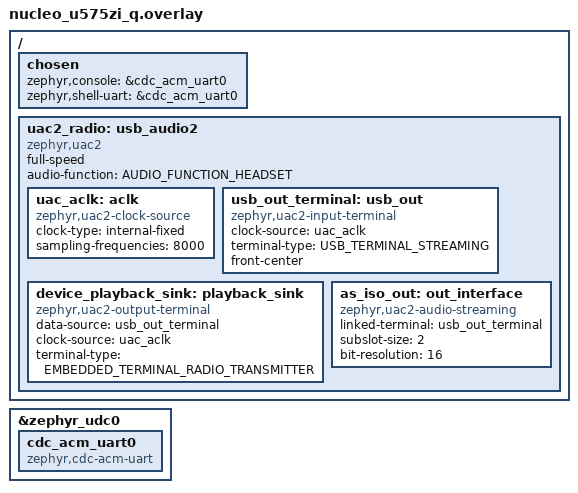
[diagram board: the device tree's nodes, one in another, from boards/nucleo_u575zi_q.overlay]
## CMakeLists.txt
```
cmake_minimum_required(VERSION 3.13.1)
find_package(Zephyr REQUIRED HINTS $ENV{ZEPHYR_BASE})

project(app LANGUAGES C CXX ASM)

target_sources(app PRIVATE src/version_shell.cpp)

if (CONFIG_ETL)
    target_sources(app PRIVATE src/etl_error_handler.cpp)
endif()

if (CONFIG_BOARD_NATIVE_SIM)
    # native_sim has no USB and no hardware-timed audio (analog-audio-in/out are
    # STM32-only); the SA818 driver runs AT/UART + control GPIOs only.
    target_sources(app PRIVATE src/main.cpp)
elseif (CONFIG_USB_DEVICE_STACK_NEXT)
    # Real hardware: 3-class USB composite (CDC-ACM + UAC2 + DFU).
    include(${ZEPHYR_BASE}/samples/subsys/usb/common/common.cmake)
    # SA818 driver public headers (<sa818/sa818.h> etc.) are only exposed via the
    # driver's own library-private include path; the app target needs it too,
    # same as subsys/module/CMakeLists.txt does for CONFIG_MODULE_SA818 and
    # tests/usb_audio/CMakeLists.txt does for this same pair of sources.
    target_include_directories(app PRIVATE
        ${CMAKE_CURRENT_LIST_DIR}/../drivers/radio/sa818
    )
    target_sources(app PRIVATE
        src/main_usb_audio.cpp
        src/usb_audio_bridge.cpp
        src/audio_stream.cpp
        src/feedback.cpp
        src/boot_confirm/health_gate.cpp
        src/boot_confirm/boot_confirm_fm.cpp
    )
    target_include_directories(app PRIVATE ${CMAKE_CURRENT_LIST_DIR}/src/boot_confirm)
    # DFU runtime->DFU-mode switch is prod-only (MCUboot); guard so the bare build never compiles it.
    if(CONFIG_BOOTLOADER_MCUBOOT)
        target_sources(app PRIVATE src/dfu_mode.cpp)
    endif()
    # Test-only bench loopback shell command (SA818 bypass); default-off Kconfig.
    if(CONFIG_FM_TEST_LOOPBACK)
        target_sources(app PRIVATE src/audio_shell.cpp)
    endif()
else()
    target_sources(app PRIVATE src/main.cpp)
endif()
```

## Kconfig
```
config FM_BOOT_CONFIRM_SKIP_SA818
	bool "Skip the SA818 handshake in the boot-confirm health gate"
	default n
	help
	  Bench/HIL-only. Drops the SA818 AT-handshake criterion from the
	  boot-confirm health gate, so a trial image can self-confirm on a
	  bench that has no working SA818 (no radio / no 12 V rail) using
	  only the USB-enumerated and shell-active criteria. Without this,
	  the SA818 probe never succeeds and every trial image reverts.
	  NEVER enable this in a production build.

menu "Zephyr"
source "Kconfig.zephyr"
endmenu

config FM_TEST_LOOPBACK
	bool "Test-only internal UAC2 audio loopback (SA818 bypass)"
	default n
	depends on USB_DEVICE_STACK_NEXT && SHELL
	help
	  Bench test mode. When armed at runtime it bridges the UAC2 OUT stream
	  (USB host -> device) straight back into the UAC2 IN stream
	  (device -> USB host), bypassing the SA818 radio entirely. Adds an
	  `audio loopback on|off|status` shell command to arm it. Intended for
	  hardware-in-the-loop verification of the host-side audio path without a
	  working radio link. Default n; never enable in a production build.

module = APP
module-str = APP
source "subsys/logging/Kconfig.template.log_config"
```

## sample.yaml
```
sample:
  description: FM Board Application
  name: fm-application

tests:
  fm.app.build:
    build_only: true
    integration_platforms:
      - fm_board
      - native_sim/native/64
  fm.app.loopback.build:
    # Build-only: verify the test-mode UAC2 loopback (SA818 bypass) compiles into
    # the fm_board app with CONFIG_FM_TEST_LOOPBACK=y. Runtime verification of the
    # audio routing is deferred to the HIL bench.
    build_only: true
    extra_configs:
      - CONFIG_FM_TEST_LOOPBACK=y
    platform_allow:
      - fm_board
    integration_platforms:
      - fm_board
    tags:
      - usb
      - audio
      - loopback
  fm.app.bench_skip_sa818.build:
    # Build-only: verify the boot-confirm health gate compiles with the SA818
    # criterion dropped (CONFIG_FM_BOOT_CONFIRM_SKIP_SA818=y) for HIL/bench use
    # without a working radio.
    build_only: true
    extra_configs:
      - CONFIG_FM_BOOT_CONFIRM_SKIP_SA818=y
    platform_allow:
      - fm_board
    integration_platforms:
      - fm_board
```

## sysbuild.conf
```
# Copyright (c) 2026 OE5XRX
# SPDX-License-Identifier: LGPL-3.0-or-later
#
# Sysbuild configuration for fm_board MCUboot + application build.
# This file is picked up automatically when building with --sysbuild.

# Build MCUboot together with the signed application.
SB_CONFIG_BOOTLOADER_MCUBOOT=y

# Swap-using-offset: scratch-less, interrupt-safe rollback (current Zephyr default).
SB_CONFIG_MCUBOOT_MODE_SWAP_USING_OFFSET=y

# ECDSA-P256 signatures (HW-accelerated by the U5 PKA in future; tinycrypt for now).
SB_CONFIG_BOOT_SIGNATURE_TYPE_ECDSA_P256=y

# Local + CI builds use MCUboot's built-in development key (root-ec-p256.pem in
# the mcuboot tree) — reproducible, not secret. Real releases override this with
# the OE5XRX production key via the CLI (-DSB_CONFIG_BOOT_SIGNATURE_KEY_FILE),
# materialized in .github/workflows/release.yml from the org secret. Never set a
# key file path here (would risk committing the key). See
# docs/superpowers/specs/2026-09-12-fw-production-signing-key-design.md.
```

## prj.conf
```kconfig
# Copyright (c) 2025 OE5XRX
# SPDX-License-Identifier: LGPL-3.0-or-later

# FM Board Application Configuration
# Main project configuration for SA818-based FM transceiver

# =============================================================================
# Language & Standard Library
# =============================================================================
CONFIG_CPP=y
CONFIG_STD_CPP20=y
CONFIG_EXTERNAL_LIBCPP=y

# =============================================================================
# Console & Serial
# =============================================================================
CONFIG_SERIAL=y
CONFIG_CONSOLE=y
CONFIG_UART_CONSOLE=y
CONFIG_PRINTK=y

# =============================================================================
# Shell Interface
# =============================================================================
CONFIG_SHELL=y
CONFIG_SHELL_BACKEND_SERIAL=y
CONFIG_SHELL_PROMPT_UART="fm> "

# Shell subsystem commands
CONFIG_KERNEL_SHELL=y
CONFIG_DEVICE_SHELL=y

# =============================================================================
# Storage
# =============================================================================
CONFIG_EEPROM=y
CONFIG_EEPROM_SHELL=y

# =============================================================================
# Device identity (STM32 96-bit UID)
# =============================================================================
# hwinfo_get_device_id() backs the runtime UID reported in `module fm describe`
# (identity.uid). On native_sim hwinfo returns -ENOSYS, so the provider falls
# back to a persisted synthetic UID (uid_source=synthetic).
CONFIG_HWINFO=y

# =============================================================================
# Peripherals
# =============================================================================

# Audio (RX capture / TX playback) is handled by the analog-audio-in /
# analog-audio-out drivers, which drive the conversions directly via STM32 LL +
# DMA. They still `select ADC`/`select DAC` so the Zephyr adc_stm32/dac_stm32
# subsystems bring the peripherals up (clocks + pinctrl) and coexist with the
# LL data path — the subsystems' streaming APIs themselves are not used.

# GPIO - SA818 control signals
CONFIG_GPIO=y
CONFIG_GPIO_SHELL=y

# UART - SA818 AT command interface
CONFIG_UART_INTERRUPT_DRIVEN=y

# =============================================================================
# Radio Driver
# =============================================================================
CONFIG_SA818=y
CONFIG_SA818_SHELL=y

# =============================================================================
# Logging
# =============================================================================
# Logs deliberately stay on the CDC-ACM control UART, but MUST route ONLY
# through the shell log backend -- NOT a second, direct UART backend.
#
# CONFIG_SHELL_BACKEND_SERIAL enables CONFIG_SHELL_LOG_BACKEND (default y): the
# shell thread serializes log flushing with its own shell_print output, so a
# MODULE-* protocol response line is emitted whole. A direct CONFIG_LOG_BACKEND_UART
# is a SECOND, async writer (LOG_PROCESS_THREAD, deferred mode) to the same UART
# with no mutual exclusion vs. the shell -- it splits MODULE-* lines mid-string and
# makes the station-agent discovery handshake flap OFFLINE. So it stays OFF.
CONFIG_LOG=y
CONFIG_LOG_DEFAULT_LEVEL=3
CONFIG_SHELL_LOG_BACKEND=y
# (CONFIG_LOG_BACKEND_UART intentionally NOT set -- see comment above.)

# =============================================================================
# Embedded Template Library (ETL)
# =============================================================================
# No-alloc fixed-capacity containers (etl::string/vector/map...). ETL routes
# runtime errors to a registered handler (see app/src/etl_error_handler.cpp)
# instead of throwing (exceptions stay disabled).
CONFIG_ETL=y
CONFIG_ETL_LOG_ERRORS=y

# =============================================================================
# Module Platform (self-describing capability interface)
# =============================================================================
# Ship the SAME interface the Twister suite tests: `module fm describe` must
# answer on the shipped app binary, not only in tests/sim_shell. MODULE_SA818
# depends on SA818 (enabled above) and selects CBPRINTF_FP_SUPPORT (needed for
# the %.4f floats in MODULE-RESULT).
CONFIG_MODULE=y
CONFIG_MODULE_SA818=y

# =============================================================================
# Reboot support
# =============================================================================
# Required by sys_reboot() used in h_reboot() (health-gate deadline revert)
# and the wdt_cb backstop timer (task_wdt stall path when the IWDG is not
# armed, prod-only).  Minimal symbol; safe in both bare and prod builds.
CONFIG_REBOOT=y

# =============================================================================
# Fault handling
# =============================================================================
# Reboot on any fatal error (bus/usage/MPU/stack-overflow fault) instead of
# halting the core forever. A halted core takes USB down with it, so the device
# just goes silent and dead until a physical power cycle -- exactly what a shell
# stack overflow used to do. Rebooting instead: the fault handler still prints
# the ESF/reason to the log UART first, then resets, so USB re-enumerates and the
# failure is observable (and on the prod/MCUboot build a persistently-faulting
# trial image is reverted by the health-gate + IWDG). Trade-off: a deterministic
# fault becomes a reboot loop rather than a hang -- intended: a visible loop is
# recoverable and diagnosable, a silent dead port is neither.
CONFIG_RESET_ON_FATAL_ERROR=y
```

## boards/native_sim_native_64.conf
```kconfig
# Copyright (c) 2025 OE5XRX
# SPDX-License-Identifier: LGPL-3.0-or-later

# Native Simulator Board-Specific Configuration
# Additional settings for native_sim/native/64 platform
# Enables hardware emulators for SA818 driver development

# =============================================================================
# Hardware Emulators
# =============================================================================

# GPIO Emulator - Required for SA818 control signals
# (power, PTT, H/L power, carrier detect). Audio is STM32-only (LL+DMA) and not
# instantiated on native_sim, so no ADC/DAC emulator is needed.
CONFIG_GPIO_EMUL=y

# =============================================================================
# UART Configuration
# =============================================================================
# UART PTY is automatically configured by native_sim
```

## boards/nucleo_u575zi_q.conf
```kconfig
CONFIG_USB_DEVICE_STACK_NEXT=y
CONFIG_USBD_CDC_ACM_CLASS=y
CONFIG_CDC_ACM_SERIAL_INITIALIZE_AT_BOOT=n

# UAC2
CONFIG_USBD_AUDIO2_CLASS=y

# Optional aber praktisch für Debug
CONFIG_USB_DEVICE_LOG_LEVEL_INF=y
CONFIG_LOG=y
```

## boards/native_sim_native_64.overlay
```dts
/*
 * Copyright (c) 2025 OE5XRX
 * SPDX-License-Identifier: LGPL-3.0-or-later
 *
 * Native Simulator Device Tree Overlay
 * Configures GPIO emulators for SA818 driver testing. The SA818 driver only
 * does AT/UART + control GPIOs; the hardware-timed audio path (analog-audio-in /
 * analog-audio-out) is STM32-only and is not instantiated on native_sim.
 */

/ {
  aliases {
    config-eeprom0 = &eeprom0;
    sa818 = &sa818;
  };

  /* Virtueller GPIO-Controller für SA818 */
  gpio_sa818: gpio_sa818 {
    compatible = "zephyr,gpio-emul";
    status = "okay";
    #gpio-cells = <2>;
    gpio-controller;
  };

  /* SA818 Device */
  sa818: sa818 {
    compatible = "sa,sa818";
    status = "okay";

    band = "vhf";
    uart = <&uart1>;

    h-l-power-gpios   = <&gpio_sa818 0 GPIO_ACTIVE_HIGH>;
    nptt-gpios        = <&gpio_sa818 1 GPIO_ACTIVE_LOW>;
    npower-down-gpios = <&gpio_sa818 2 GPIO_ACTIVE_LOW>;
    nsquelch-gpios    = <&gpio_sa818 3 GPIO_ACTIVE_LOW>;

    tx-enable-delay-ms = <20>;
    rx-settle-time-ms  = <50>;
  };
};

&uart1 {
  status = "okay";
  current-speed = <9600>;
};
```

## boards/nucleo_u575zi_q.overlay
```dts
#include <zephyr/dt-bindings/usb/audio.h>

/ {
  chosen {
    zephyr,console = &cdc_acm_uart0;
    zephyr,shell-uart = &cdc_acm_uart0;
  };

  /*
   * USB Audio Class 2 (UAC2)
   * - Playback (OUT): Host -> Device  (z.B. SA818 TX / DAC)
   * - Capture  (IN):  Device -> Host  (z.B. SA818 RX / ADC)
   *
   * If you only need playback first, you can comment out the IN path.
   */
  uac2_radio: usb_audio2 {
    compatible = "zephyr,uac2";
    status = "okay";
    full-speed;
		audio-function = <AUDIO_FUNCTION_HEADSET>;

    /* Clock Source: fixed 8kHz */
    uac_aclk: aclk {
      compatible = "zephyr,uac2-clock-source";
      clock-type = "internal-fixed";
      sampling-frequencies = <8000>;
      /* optionally:
       * frequency-control = "read-only";
       */
    };

    /* ===== Playback path (Host -> Device) ===== */

    usb_out_terminal: usb_out {
      compatible = "zephyr,uac2-input-terminal";
      clock-source = <&uac_aclk>;
      terminal-type = <USB_TERMINAL_STREAMING>;
      front-center; /* mono */
    };

    device_playback_sink: playback_sink {
      compatible = "zephyr,uac2-output-terminal";
      data-source = <&usb_out_terminal>;
      clock-source = <&uac_aclk>;
      /* pick something that matches your use-case; radio transmitter works too */
      terminal-type = <EMBEDDED_TERMINAL_RADIO_TRANSMITTER>;
    };

    as_iso_out: out_interface {
      compatible = "zephyr,uac2-audio-streaming";
      linked-terminal = <&usb_out_terminal>;
      subslot-size = <2>;
      bit-resolution = <16>;

      /*
       * If your host/ALSA expects asynchronous OUT with explicit feedback,
       * enable exactly one of these depending on how Zephyr currently implements it:
       *
       * - implicit-feedback;          (feedback on IN endpoint, no separate sync EP)
       * - feedback-endpoint;          (if such property exists in your Zephyr rev)
       *
       * Keep it commented for first bring-up and enable only if needed.
       */
      // implicit-feedback;
    };

    /* ===== Capture path (Device -> Host) ===== */

    //device_capture_source: capture_src {
    //  compatible = "zephyr,uac2-input-terminal";
    //  clock-source = <&uac_aclk>;
    //  terminal-type = <EMBEDDED_TERMINAL_RADIO_RECEIVER>;
    //  front-center; /* mono */
    //};
//
    //usb_in_terminal: usb_in {
    //  compatible = "zephyr,uac2-output-terminal";
    //  data-source = <&device_capture_source>;
    //  clock-source = <&uac_aclk>;
    //  terminal-type = <USB_TERMINAL_STREAMING>;
    //};
//
    //as_iso_in: in_interface {
    //  compatible = "zephyr,uac2-audio-streaming";
    //  linked-terminal = <&usb_in_terminal>;
    //  subslot-size = <2>;
    //  bit-resolution = <16>;
    //  // implicit-feedback;
    //};
  };
};

&zephyr_udc0 {
  cdc_acm_uart0: cdc_acm_uart0 {
    compatible = "zephyr,cdc-acm-uart";
  };
};
```

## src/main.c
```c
#include <zephyr/kernel.h>
#include <zephyr/sys/printk.h>

int main(void) {
  printk("Hello from Zephyr native_sim!\n");
  return 0;
}
```

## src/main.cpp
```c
/**
 * @file main.cpp
 * @brief FM Transceiver Main Application
 *
 * @copyright Copyright (c) 2026 OE5XRX
 * @spdx-license-identifier LGPL-3.0-or-later
 */

#include "audio_bridge/bridge.h"

#include <zephyr/device.h>
#include <zephyr/kernel.h>
#include <zephyr/logging/log.h>
#include <zephyr/sys/printk.h>

LOG_MODULE_REGISTER(main, LOG_LEVEL_INF);

int main(void) {}

/*
static int init_audio_bridge(void) {
  LOG_INF("FM Transceiver Application Starting");

  // Get device references from device tree
  const struct device *sa818_dev = DEVICE_DT_GET(DT_ALIAS(sa818));
  if (!device_is_ready(sa818_dev)) {
    LOG_ERR("SA818 device not ready");
    return -ENODEV;
  }
  LOG_INF("SA818 device ready");

  const struct device *uac2_dev = DEVICE_DT_GET(DT_NODELABEL(uac2_radio));
  if (!device_is_ready(uac2_dev)) {
    LOG_ERR("UAC2 device not ready");
    return -ENODEV;
  }
  LOG_INF("UAC2 device ready");

  // Initialize USB Audio Bridge to connect USB UAC2 with SA818
  int ret = oe5xrx::audio::UsbAudioBridge::instance().initialize(sa818_dev, uac2_dev);
  if (ret != 0) {
    LOG_ERR("Failed to initialize USB Audio Bridge: %d", ret);
    return ret;
  }

  LOG_INF("System initialization complete");
  LOG_INF("USB Audio <-> SA818 Radio bridge active");

  return 0;
}

SYS_INIT(init_audio_bridge, APPLICATION, 80);
*/
```

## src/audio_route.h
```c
/**
 * @file audio_route.h
 * @brief Pure routing decision for the UAC2 audio tap (USB OUT / SA818 RX).
 *
 * Single source of truth for *where* an audio chunk goes in the USB audio
 * bridge, factored out of usb_audio_bridge.cpp so the decision is unit-testable
 * on native_sim without the USB device stack (which the bridge translation unit
 * pulls in and native_sim does not provide). The functions are pure, constexpr,
 * and have no RTOS/USB/heap dependencies.
 *
 * Production behaviour (CONFIG_FM_TEST_LOOPBACK=n): the bridge always passes
 * loopback_enabled == false, so classify_out() folds to OutRoute::TxRing and
 * classify_sa818_rx() folds to Sa818RxRoute::RxRing -- the normal
 * USB OUT -> SA818 TX and SA818 RX -> USB IN paths, unchanged.
 *
 * @copyright Copyright (c) 2026 OE5XRX
 * @spdx-license-identifier LGPL-3.0-or-later
 */

#ifndef AUDIO_ROUTE_H_
#define AUDIO_ROUTE_H_

namespace audio_route {

/** Destination for a just-received USB OUT (host -> device) PCM chunk. */
enum class OutRoute {
  /** Normal operation: OUT -> TX ring -> SA818 TX. */
  TxRing,
  /** Test loopback armed and USB IN active: OUT -> RX ring -> USB IN (SA818 bypassed). */
  RxRingLoopback,
  /** Test loopback armed but USB IN inactive: drop. Buffering here would fill the
   *  RX ring with stale audio that plays out delayed (or overflows) once IN comes up. */
  DropInInactive,
};

/** Destination for an SA818 RX capture chunk. */
enum class Sa818RxRoute {
  /** Normal operation: SA818 RX -> RX ring -> USB IN. */
  RxRing,
  /** Test loopback armed: drop, so the real capture cannot mix into the RX ring
   *  which is carrying the looped-back USB OUT audio. */
  DropLoopback,
};

/**
 * @brief Decide where a USB OUT PCM chunk is routed.
 * @param loopback_enabled test loopback armed at runtime
 * @param rx_enabled USB IN (device -> host) terminal currently active
 */
constexpr OutRoute classify_out(bool loopback_enabled, bool rx_enabled) {
  if (!loopback_enabled) {
    return OutRoute::TxRing;
  }
  return rx_enabled ? OutRoute::RxRingLoopback : OutRoute::DropInInactive;
}

/**
 * @brief Decide where an SA818 RX capture chunk is routed.
 * @param loopback_enabled test loopback armed at runtime
 */
constexpr Sa818RxRoute classify_sa818_rx(bool loopback_enabled) {
  return loopback_enabled ? Sa818RxRoute::DropLoopback : Sa818RxRoute::RxRing;
}

} // namespace audio_route

#endif /* AUDIO_ROUTE_H_ */
```

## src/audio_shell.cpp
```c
/*
 * Copyright (c) 2026 OE5XRX
 * SPDX-License-Identifier: LGPL-3.0-or-later
 *
 * `audio` shell command tree — test-only UAC2 internal loopback control.
 *
 * `audio loopback on|off|status` arms/disarms the bench test mode that routes
 * USB OUT (host -> device) audio straight back to USB IN (device -> host),
 * bypassing the SA818. Lets the host-side audio path be exercised without a
 * working radio link (drives the HIL audio-loopback gate). Compiled only when
 * CONFIG_FM_TEST_LOOPBACK is set (default n); never present in a production
 * build.
 */
#include "usb_audio_bridge.h"

#include <zephyr/shell/shell.h>

static int cmd_loopback_on(const struct shell *sh, size_t argc, char **argv) {
  ARG_UNUSED(argc);
  ARG_UNUSED(argv);
  usb_audio_bridge_set_loopback(true);
  shell_print(sh, "loopback enabled (USB OUT -> USB IN, SA818 bypassed)");
  return 0;
}

static int cmd_loopback_off(const struct shell *sh, size_t argc, char **argv) {
  ARG_UNUSED(argc);
  ARG_UNUSED(argv);
  usb_audio_bridge_set_loopback(false);
  shell_print(sh, "loopback disabled");
  return 0;
}

static int cmd_loopback_status(const struct shell *sh, size_t argc, char **argv) {
  ARG_UNUSED(argc);
  ARG_UNUSED(argv);
  shell_print(sh, "loopback: %s", usb_audio_bridge_get_loopback() ? "on" : "off");
  return 0;
}

SHELL_STATIC_SUBCMD_SET_CREATE(loopback_subcmds, SHELL_CMD(on, NULL, "Enable internal UAC2 loopback (SA818 bypass)", cmd_loopback_on),
                               SHELL_CMD(off, NULL, "Disable internal UAC2 loopback", cmd_loopback_off),
                               SHELL_CMD(status, NULL, "Show loopback state", cmd_loopback_status), SHELL_SUBCMD_SET_END);

SHELL_STATIC_SUBCMD_SET_CREATE(audio_subcmds, SHELL_CMD(loopback, &loopback_subcmds, "Test-only UAC2 internal loopback (SA818 bypass)", NULL),
                               SHELL_SUBCMD_SET_END);

SHELL_CMD_REGISTER(audio, &audio_subcmds, "Audio test controls (bench/HIL only)", NULL);
```

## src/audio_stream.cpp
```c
/**
 * @file audio_stream.cpp
 * @brief Generic hardware-timed audio streaming bridge. See audio_stream.h.
 *
 * Bridges application audio callbacks to the hardware-timed capture/playback
 * backend (the analog-audio-in / analog-audio-out TIM+ADC/DAC+DMA modules). It
 * is radio-agnostic: the @p dev handle is opaque and only passed back to the
 * callbacks as context.
 *
 * @copyright Copyright (c) 2026 OE5XRX
 * @spdx-license-identifier LGPL-3.0-or-later
 */

#include "audio_stream.h"

#include <errno.h>
#include <zephyr/device.h>
#include <zephyr/kernel.h>
#include <zephyr/logging/log.h>

/* Require the DT node to be status=okay AND the driver Kconfig on. The device
 * is only instantiated via DT_INST_FOREACH_STATUS_OKAY, so an existing-but-
 * disabled node (or CONFIG_ANALOG_AUDIO_{IN,OUT}=n) has no device symbol and
 * DEVICE_DT_GET() would fail to link. Use HAS_STATUS(okay), not NODE_EXISTS. */
#if DT_NODE_HAS_STATUS(DT_NODELABEL(audio_in), okay) && IS_ENABLED(CONFIG_ANALOG_AUDIO_IN)
#include <oe5xrx/audio/analog_audio_in.h>
#define AUDIO_STREAM_HAVE_AAI 1
#endif

#if DT_NODE_HAS_STATUS(DT_NODELABEL(audio_out), okay) && IS_ENABLED(CONFIG_ANALOG_AUDIO_OUT)
#include <oe5xrx/audio/analog_audio_out.h>
#define AUDIO_STREAM_HAVE_AAO 1
#endif

LOG_MODULE_REGISTER(audio_stream, LOG_LEVEL_INF);

#define AUDIO_STREAM_SAMPLE_SIZE 2 /* 16-bit = 2 bytes */

/** Audio streaming context. */
struct audio_stream_ctx {
  const struct device *dev;
  struct audio_stream_callbacks callbacks;
  struct audio_format format;
  bool streaming;
};

/*
 * DESIGN NOTE: single global streaming context — only one audio stream can be
 * active at a time, which fits the single-radio system. Storing the context per
 * device would be needed to support several concurrent streams.
 */

/* Static mutex for the streaming context - initialized at compile time */
K_MUTEX_DEFINE(audio_stream_mutex);

static struct audio_stream_ctx audio_ctx;

#ifdef AUDIO_STREAM_HAVE_AAO
/* Hardware-timed TX playback pull-source for the analog-audio-out module. Runs
 * in that module's workqueue thread (thread context, may take a mutex). Sources
 * signed 16-bit PCM from the application via the tx_request callback. Returning
 * fewer than @p max samples (or 0 when there is no data) makes the module emit
 * mid-scale silence for the shortfall; the consumer gates whether any data is
 * available. Host PCM is little-endian, matching the Cortex-M, so the byte
 * buffer maps directly onto int16 samples with no swap. */
static size_t audio_stream_tx_src(int16_t *dst, size_t max, void *user) {
  struct audio_stream_ctx *ctx = static_cast<struct audio_stream_ctx *>(user);

  if (!ctx->callbacks.tx_request) {
    return 0;
  }
  size_t bytes = ctx->callbacks.tx_request(ctx->dev, reinterpret_cast<uint8_t *>(dst), max * AUDIO_STREAM_SAMPLE_SIZE, ctx->callbacks.user_data);
  /* Defend against a callback that returns more than requested; the division to
   * whole samples already rounds a stray odd byte down. */
  if (bytes > max * AUDIO_STREAM_SAMPLE_SIZE) {
    bytes = max * AUDIO_STREAM_SAMPLE_SIZE;
  }
  return bytes / AUDIO_STREAM_SAMPLE_SIZE;
}
#endif

#ifdef AUDIO_STREAM_HAVE_AAI
/* Hardware-timed RX samples from the analog-audio-in module. Runs in the module's
 * workqueue thread (not an ISR), so forwarding through rx_data (which may take a
 * mutex) is safe. */
static void audio_stream_on_rx_samples(const int16_t *samples, size_t count, void *user) {
  struct audio_stream_ctx *ctx = static_cast<struct audio_stream_ctx *>(user);

  if (ctx->callbacks.rx_data) {
    ctx->callbacks.rx_data(ctx->dev, reinterpret_cast<const uint8_t *>(samples), count * AUDIO_STREAM_SAMPLE_SIZE, ctx->callbacks.user_data);
  }
}
#endif

int audio_stream_register(const struct device *dev, const struct audio_stream_callbacks *callbacks) {
  if (!dev || !callbacks) {
    return -EINVAL;
  }

  /* Guard the shared context and refuse to swap callbacks under a running
   * stream (the backend threads read ctx->callbacks/ctx->dev while active). */
  k_mutex_lock(&audio_stream_mutex, K_FOREVER);
  if (audio_ctx.streaming) {
    k_mutex_unlock(&audio_stream_mutex);
    return -EBUSY;
  }
  audio_ctx.dev = dev;
  audio_ctx.callbacks = *callbacks;
  k_mutex_unlock(&audio_stream_mutex);

  LOG_INF("Audio callbacks registered");
  return 0;
}

int audio_stream_start(const struct device *dev, const struct audio_format *format) {
  if (!dev || !format) {
    return -EINVAL;
  }

  /* Hold the stream mutex across the whole start sequence — the state flip AND
   * the backend bring-up. Releasing it before starting the backends would open
   * a window where a concurrent stop() clears streaming while we are still
   * bringing hardware up, leaving the backends running with streaming == false.
   * The backend callbacks (tx_src / on_rx_samples) do not take this mutex, so
   * holding it across analog_audio_*_start() cannot deadlock. */
  k_mutex_lock(&audio_stream_mutex, K_FOREVER);
  if (audio_ctx.dev != dev) {
    /* start must run against the context bound by audio_stream_register();
     * a mismatch (or a start without a prior register, dev == NULL) would
     * later trip the dev checks in stop()/get_format(). */
    k_mutex_unlock(&audio_stream_mutex);
    LOG_ERR("audio_stream_start dev does not match registered context");
    return -EINVAL;
  }
  if (audio_ctx.streaming) {
    k_mutex_unlock(&audio_stream_mutex);
    LOG_WRN("Audio streaming already active");
    return 0;
  }
  audio_ctx.format = *format;
  audio_ctx.streaming = true;

  /* Count backends that actually came up. A single backend failing only
   * degrades that direction (RX-only or TX-only is still useful), so we keep
   * streaming. But if *no* backend is driving the callbacks — none compiled in,
   * or every one failed — then reporting success would be a lie: the rings
   * would never be drained/filled. In that case roll back and fail with
   * -ENODEV. */
  int started = 0;

#ifdef AUDIO_STREAM_HAVE_AAO
  /* Start the hardware-timed TX playback module; it pulls PCM via the source
   * callback. A failure only disables TX playback (RX still works), so surface
   * it loudly rather than fail the whole stream. */
  const struct device *aao_dev = DEVICE_DT_GET(DT_NODELABEL(audio_out));
  if (!device_is_ready(aao_dev)) {
    LOG_ERR("analog-audio-out device not ready (TX playback unavailable)");
  } else {
    int aao_ret = analog_audio_out_start(aao_dev, audio_stream_tx_src, &audio_ctx);
    if (aao_ret < 0) {
      LOG_ERR("analog-audio-out start failed: %d (TX playback unavailable)", aao_ret);
    } else {
      started++;
    }
  }
#endif

#ifdef AUDIO_STREAM_HAVE_AAI
  /* Start the hardware-timed RX capture module; it delivers PCM via the callback.
   * A failure only disables RX capture (TX still works), so surface it loudly
   * rather than fail the whole stream. Verify the device initialised before use
   * (per the driver-layer device_is_ready() convention) so a failed init cannot
   * leave analog_audio_in_start() operating on uninitialised runtime state. */
  const struct device *aai_dev = DEVICE_DT_GET(DT_NODELABEL(audio_in));
  if (!device_is_ready(aai_dev)) {
    LOG_ERR("analog-audio-in device not ready (RX capture unavailable)");
  } else {
    int aai_ret = analog_audio_in_start(aai_dev, audio_stream_on_rx_samples, &audio_ctx);
    if (aai_ret < 0) {
      LOG_ERR("analog-audio-in start failed: %d (RX capture unavailable)", aai_ret);
    } else {
      started++;
    }
  }
#endif

  if (started == 0) {
    audio_ctx.streaming = false;
    k_mutex_unlock(&audio_stream_mutex);
    LOG_ERR("No audio backend available; not streaming");
    return -ENODEV;
  }

  k_mutex_unlock(&audio_stream_mutex);
  LOG_INF("Audio streaming started: %u Hz, %u-bit, %u ch", format->sample_rate, format->bit_depth, format->channels);

  return 0;
}

int audio_stream_stop(const struct device *dev) {
  if (!dev) {
    return -EINVAL;
  }

  /* Hold the mutex across the state flip AND the backend teardown so stop() is
   * fully serialized against start() (see the note there) — otherwise the two
   * could interleave and leave a backend running with streaming == false. */
  k_mutex_lock(&audio_stream_mutex, K_FOREVER);
  if (audio_ctx.dev != dev) {
    /* Not the registered/active context — refuse to stop someone else's stream. */
    k_mutex_unlock(&audio_stream_mutex);
    return -EINVAL;
  }
  audio_ctx.streaming = false;

#ifdef AUDIO_STREAM_HAVE_AAO
  /* Consume the result: the analog_audio_* stop functions are warn_unused_result,
   * and GCC's attribute (unlike [[nodiscard]]) is NOT silenced by a (void) cast. */
  int aao_stop_ret = analog_audio_out_stop(DEVICE_DT_GET(DT_NODELABEL(audio_out)));
  if (aao_stop_ret < 0) {
    LOG_WRN("analog-audio-out stop returned %d", aao_stop_ret);
  }
#endif

#ifdef AUDIO_STREAM_HAVE_AAI
  int aai_stop_ret = analog_audio_in_stop(DEVICE_DT_GET(DT_NODELABEL(audio_in)));
  if (aai_stop_ret < 0) {
    LOG_WRN("analog-audio-in stop returned %d", aai_stop_ret);
  }
#endif

  k_mutex_unlock(&audio_stream_mutex);
  LOG_INF("Audio streaming stopped");
  return 0;
}

int audio_stream_get_format(const struct device *dev, struct audio_format *format) {
  if (!dev || !format) {
    return -EINVAL;
  }

  k_mutex_lock(&audio_stream_mutex, K_FOREVER);
  if (audio_ctx.dev != dev) {
    k_mutex_unlock(&audio_stream_mutex);
    return -EINVAL;
  }
  *format = audio_ctx.format;
  k_mutex_unlock(&audio_stream_mutex);
  return 0;
}
```

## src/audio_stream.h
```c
/**
 * @file audio_stream.h
 * @brief Generic hardware-timed audio streaming bridge
 *
 * Callback-based bidirectional audio streaming that connects an application
 * audio source/sink (USB, I2S, file, network, ...) to the hardware-timed
 * capture/playback backend. The sample timing is delegated to that backend
 * (currently the analog-audio-in / analog-audio-out TIM+ADC/DAC+DMA modules);
 * this layer only bridges PCM to/from the application callbacks.
 *
 * This module is intentionally radio-agnostic: it takes an opaque @p dev handle
 * that it passes straight back to the callbacks as context, and depends on no
 * particular transceiver driver. Swapping the audio backend (e.g. to an I2S
 * codec) is a change here, not in the radio driver.
 *
 * @copyright Copyright (c) 2026 OE5XRX
 * @spdx-license-identifier LGPL-3.0-or-later
 */

#ifndef OE5XRX_APP_AUDIO_STREAM_H_
#define OE5XRX_APP_AUDIO_STREAM_H_

#include <stddef.h>
#include <stdint.h>
#include <zephyr/device.h>

#ifdef __cplusplus
extern "C" {
#endif

/** Audio sample format. */
struct audio_format {
  uint32_t sample_rate; /**< Sample rate in Hz (typically 8000) */
  uint8_t bit_depth;    /**< Bits per sample (typically 16) */
  uint8_t channels;     /**< Number of channels (1=mono, 2=stereo) */
};

/**
 * @brief TX audio request callback
 *
 * Invoked when the playback backend needs PCM samples. Fill @p buffer and
 * return the number of bytes written (0 when no data is available).
 *
 * @param dev       Opaque context handle from audio_stream_register()
 * @param buffer    Buffer to fill with PCM audio
 * @param size      Number of bytes requested
 * @param user_data User data pointer from callback registration
 * @return Bytes written to @p buffer
 */
typedef size_t (*audio_stream_tx_request_cb)(const struct device *dev, uint8_t *buffer, size_t size, void *user_data);

/**
 * @brief RX audio data callback
 *
 * Invoked when the capture backend has PCM samples available.
 *
 * @param dev       Opaque context handle from audio_stream_register()
 * @param buffer    Buffer containing PCM audio
 * @param size      Number of bytes in @p buffer
 * @param user_data User data pointer from callback registration
 */
typedef void (*audio_stream_rx_data_cb)(const struct device *dev, const uint8_t *buffer, size_t size, void *user_data);

/** Audio streaming callbacks. */
struct audio_stream_callbacks {
  audio_stream_tx_request_cb tx_request; /**< TX audio request (playback) */
  audio_stream_rx_data_cb rx_data;       /**< RX audio available (capture) */
  void *user_data;                       /**< User data for the callbacks */
};

/**
 * @brief Register audio streaming callbacks.
 * @param dev       Opaque context handle passed back to the callbacks.
 * @param callbacks Callback structure.
 * @return 0 on success, negative errno otherwise.
 */
int audio_stream_register(const struct device *dev, const struct audio_stream_callbacks *callbacks);

/**
 * @brief Start audio streaming (starts the capture/playback backend).
 * @return 0 on success, negative errno otherwise.
 */
int audio_stream_start(const struct device *dev, const struct audio_format *format);

/**
 * @brief Stop audio streaming.
 * @return 0 on success, negative errno otherwise.
 */
int audio_stream_stop(const struct device *dev);

/**
 * @brief Get the current audio format.
 * @return 0 on success, negative errno otherwise.
 */
int audio_stream_get_format(const struct device *dev, struct audio_format *format);

#ifdef __cplusplus
}
#endif

#endif /* OE5XRX_APP_AUDIO_STREAM_H_ */
```

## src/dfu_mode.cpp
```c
/**
 * @file dfu_mode.cpp
 * @brief DFU-only mode context: composite→DFU switch and upgrade request.
 *
 * Mirrors the switch_to_dfu_mode() sequence from
 * zephyr/samples/subsys/usb/dfu/src/main.c, adapted for C++20 and the OE5XRX
 * project conventions (no dynamic allocation, no exceptions, no RTTI).
 *
 * Compiled only when CONFIG_BOOTLOADER_MCUBOOT is set (prod/sysbuild build).
 *
 * @copyright Copyright (c) 2026 OE5XRX
 * @spdx-license-identifier LGPL-3.0-or-later
 */

#ifdef CONFIG_BOOTLOADER_MCUBOOT

#include "dfu_mode.h"

#include <zephyr/dfu/mcuboot.h>
#include <zephyr/kernel.h>
#include <zephyr/logging/log.h>
#include <zephyr/sys/reboot.h>
#include <zephyr/usb/usbd.h>

extern "C" {
#include "sample_usbd.h"
}

LOG_MODULE_REGISTER(dfu_mode, LOG_LEVEL_INF);

/* ---------------------------------------------------------------------------
 * Deferred self-reboot after a completed DFU download.
 *
 * The remote station has no debugger/ST-Link, so the reset that triggers the
 * MCUboot swap must originate from the firmware itself over the USB/DFU path.
 * We must NOT reboot synchronously inside the USBD message callback: that would
 * cut off dfu-util's final DFU status / manifestation phase and it would report
 * an error instead of "Done".  Instead we schedule a short delayed cold reboot
 * so the DFU manifestation and USB status complete cleanly first, then reset.
 * --------------------------------------------------------------------------*/
static constexpr uint32_t DFU_REBOOT_DELAY_MS = 500;

static void dfu_reboot_work_handler(struct k_work *work) {
  ARG_UNUSED(work);
  LOG_INF("DFU: rebooting to let MCUboot swap in the new image");
  sys_reboot(SYS_REBOOT_COLD);
}

static K_WORK_DELAYABLE_DEFINE(dfu_reboot_work, dfu_reboot_work_handler);

/* ---------------------------------------------------------------------------
 * Static DFU-only USBD context.
 *
 * A separate USBD_DEVICE_DEFINE is required: the composite context is shut
 * down before DFU mode is entered, so we cannot reuse it.  The same UDC
 * controller node (zephyr_udc0) is shared — that is intentional; only one
 * context is active at a time.
 *
 * VID/PID reuse the same CONFIG_SAMPLE_USBD_VID / CONFIG_SAMPLE_USBD_PID
 * values as the composite so dfu-util can identify the device consistently.
 * --------------------------------------------------------------------------*/
USBD_DEVICE_DEFINE(dfu_usbd, DEVICE_DT_GET(DT_NODELABEL(zephyr_udc0)), CONFIG_SAMPLE_USBD_VID, CONFIG_SAMPLE_USBD_PID);

/* Language descriptor (mandatory, must be added before configurations). */
USBD_DESC_LANG_DEFINE(dfu_lang);

/* Configuration descriptors for FS (and optionally HS). */
USBD_DESC_CONFIG_DEFINE(dfu_fs_cfg_desc, "DFU FS Configuration");
USBD_DESC_CONFIG_DEFINE(dfu_hs_cfg_desc, "DFU HS Configuration");

static const uint8_t dfu_cfg_attributes =
    (IS_ENABLED(CONFIG_SAMPLE_USBD_SELF_POWERED) ? USB_SCD_SELF_POWERED : 0) | (IS_ENABLED(CONFIG_SAMPLE_USBD_REMOTE_WAKEUP) ? USB_SCD_REMOTE_WAKEUP : 0);

USBD_CONFIGURATION_DEFINE(dfu_fs_config, dfu_cfg_attributes, CONFIG_SAMPLE_USBD_MAX_POWER, &dfu_fs_cfg_desc);

USBD_CONFIGURATION_DEFINE(dfu_hs_config, dfu_cfg_attributes, CONFIG_SAMPLE_USBD_MAX_POWER, &dfu_hs_cfg_desc);

/* ---------------------------------------------------------------------------
 * DFU-only message callback
 * --------------------------------------------------------------------------*/
static void dfu_msg_cb(struct usbd_context *const ctx, const struct usbd_msg *const msg) {
  ARG_UNUSED(ctx);
  LOG_INF("DFU mode USBD message: %s", usbd_msg_type_string(msg->type));

  if (msg->type == USBD_MSG_DFU_DOWNLOAD_COMPLETED) {
    dfu_mode_download_completed();
  }
}

/* ---------------------------------------------------------------------------
 * Public API
 * --------------------------------------------------------------------------*/

void dfu_mode_switch_to_dfu(struct usbd_context *composite) {
  int err;

  LOG_INF("DFU detach: tearing down composite USB device");
  usbd_disable(composite);
  usbd_shutdown(composite);

  /* Build the DFU-only context.
   * Follow the sample sequence exactly:
   *   1. add language descriptor
   *   2. add HS config + register dfu_dfu class (if HS capable)
   *   3. add FS config + register dfu_dfu class
   *   4. set code triple (DFU: 0,0,0)
   *   5. init
   *   6. register msg callback
   *   7. enable
   */

  err = usbd_add_descriptor(&dfu_usbd, &dfu_lang);
  if (err) {
    LOG_ERR("DFU: failed to add language descriptor (%d) — rebooting", err);
    sys_reboot(SYS_REBOOT_COLD);
  }

  if (usbd_caps_speed(&dfu_usbd) == USBD_SPEED_HS) {
    err = usbd_add_configuration(&dfu_usbd, USBD_SPEED_HS, &dfu_hs_config);
    if (err) {
      LOG_ERR("DFU: failed to add HS configuration (%d) — rebooting", err);
      sys_reboot(SYS_REBOOT_COLD);
    }

    err = usbd_register_class(&dfu_usbd, "dfu_dfu", USBD_SPEED_HS, 1);
    if (err) {
      LOG_ERR("DFU: failed to register dfu_dfu class (HS) (%d) — rebooting", err);
      sys_reboot(SYS_REBOOT_COLD);
    }

    usbd_device_set_code_triple(&dfu_usbd, USBD_SPEED_HS, 0, 0, 0);
  }

  err = usbd_add_configuration(&dfu_usbd, USBD_SPEED_FS, &dfu_fs_config);
  if (err) {
    LOG_ERR("DFU: failed to add FS configuration (%d) — rebooting", err);
    sys_reboot(SYS_REBOOT_COLD);
  }

  err = usbd_register_class(&dfu_usbd, "dfu_dfu", USBD_SPEED_FS, 1);
  if (err) {
    LOG_ERR("DFU: failed to register dfu_dfu class (FS) (%d) — rebooting", err);
    sys_reboot(SYS_REBOOT_COLD);
  }

  usbd_device_set_code_triple(&dfu_usbd, USBD_SPEED_FS, 0, 0, 0);

  err = usbd_init(&dfu_usbd);
  if (err) {
    LOG_ERR("DFU: failed to initialize DFU-only USB device (%d) — rebooting", err);
    sys_reboot(SYS_REBOOT_COLD);
  }

  err = usbd_msg_register_cb(&dfu_usbd, dfu_msg_cb);
  if (err) {
    LOG_ERR("DFU: failed to register DFU message callback (%d) — rebooting", err);
    sys_reboot(SYS_REBOOT_COLD);
  }

  err = usbd_enable(&dfu_usbd);
  if (err) {
    LOG_ERR("DFU: failed to enable DFU-only USB device (%d) — rebooting", err);
    sys_reboot(SYS_REBOOT_COLD);
  }

  LOG_INF("DFU mode active — waiting for download");
}

void dfu_mode_download_completed(void) {
  LOG_INF("DFU download completed — requesting upgrade and scheduling self-reboot");
  int err = boot_request_upgrade(false);
  if (err != 0) {
    LOG_ERR("boot_request_upgrade failed: %d", err);
    return;
  }

  /* Defer the reset so dfu-util's DFU manifestation/status phase completes
   * cleanly before the USB link drops.  On reboot MCUboot swaps in slot1 and
   * starts the trial boot; the health gate confirms or IWDG reverts. */
  k_work_schedule(&dfu_reboot_work, K_MSEC(DFU_REBOOT_DELAY_MS));
}

#endif /* CONFIG_BOOTLOADER_MCUBOOT */
```

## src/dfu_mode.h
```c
/**
 * @file dfu_mode.h
 * @brief DFU-only mode switch support for MCUboot-enabled prod builds.
 *
 * When the composite USB device receives DFU_DETACH (USBD_MSG_DFU_APP_DETACH),
 * the composite context must be torn down and replaced with a DFU-only context
 * so the host can download a new image to slot1.
 *
 * This module is compiled only when CONFIG_BOOTLOADER_MCUBOOT is set (i.e. the
 * sysbuild / prod variant).  The bare build never includes it.
 *
 * @copyright Copyright (c) 2026 OE5XRX
 * @spdx-license-identifier LGPL-3.0-or-later
 */

#pragma once

#ifdef CONFIG_BOOTLOADER_MCUBOOT

#include <zephyr/usb/usbd.h>

#ifdef __cplusplus
extern "C" {
#endif

/**
 * @brief Switch from composite runtime mode to DFU-only mode.
 *
 * Must be called from the USBD message callback on USBD_MSG_DFU_APP_DETACH.
 * Tears down @p composite, builds a DFU-only USBD context, and enables it.
 * The DFU-only context registers its own message callback that handles
 * USBD_MSG_DFU_DOWNLOAD_COMPLETED by calling boot_request_upgrade(false).
 *
 * @param composite  The currently active composite usbd_context.
 */
void dfu_mode_switch_to_dfu(struct usbd_context *composite);

/**
 * @brief Request an upgrade and self-reboot (called after DFU download done).
 *
 * Sets the MCUboot upgrade flag, then schedules a short delayed cold reboot so
 * the DFU manifestation completes cleanly and the station swaps in the new
 * image without an external reset (there is no debugger on the board).  On the
 * following trial boot the health gate confirms the new image only after all
 * health criteria pass; if they do not, the IWDG fires and MCUboot reverts
 * automatically.
 */
void dfu_mode_download_completed(void);

#ifdef __cplusplus
}
#endif

#endif /* CONFIG_BOOTLOADER_MCUBOOT */
```

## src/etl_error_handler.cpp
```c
/*
 * Copyright (c) 2025 OE5XRX
 * SPDX-License-Identifier: LGPL-3.0-or-later
 *
 * Routes ETL runtime errors to Zephyr. ETL is built with exceptions disabled
 * and CONFIG_ETL_LOG_ERRORS=y, so on a failed check ETL invokes the registered
 * error handler instead of throwing. We fail fast: report the error, then panic.
 * Registered automatically via SYS_INIT at PRE_KERNEL_1 (priority 0) so the
 * fail-fast callback is armed before essentially all other init - an ETL check
 * failing during early boot must panic, not silently continue. set_callback only
 * writes a static pointer and touches no kernel services, so it is safe this early.
 *
 * The callback uses printk rather than LOG_ERR: it can run at any boot stage
 * (including before the logging subsystem is up), and printk is synchronous and
 * early-boot-safe, so the diagnostic is emitted before k_panic() halts.
 */

#include <etl/error_handler.h>
#include <etl/exception.h>
#include <zephyr/init.h>
#include <zephyr/kernel.h>
#include <zephyr/sys/printk.h>

namespace {

void etl_error(const etl::exception &e) {
  printk("ETL error: %s @ %s:%d\n", e.what(), e.file_name(), e.line_number());
  k_panic();
}

int etl_register_error_handler(void) {
  etl::error_handler::set_callback<etl_error>();
  return 0;
}

} // namespace

SYS_INIT(etl_register_error_handler, PRE_KERNEL_1, 0);
```

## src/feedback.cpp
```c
/**
 * @file feedback.cpp
 * @brief BufferFeedback PI regulator implementation. See feedback.h.
 *
 * @copyright Copyright (c) 2025 OE5XRX
 * @spdx-license-identifier LGPL-3.0-or-later
 */
#include "feedback.h"

namespace usb_audio {

void BufferFeedback::init(uint16_t samples_per_sof) {
  nominal_ = static_cast<uint32_t>(samples_per_sof) << kFracBits;
  clamp_ = 1 << (kFracBits - 1); /* ±0.5 sample */
  integ_limit_ = clamp_ * kTi;   /* integrator alone tops out at the clamp */
  reset();
}

void BufferFeedback::reset() {
  integrator_ = 0;
  fb_value_ = nominal_;
}

void BufferFeedback::update(size_t used, size_t capacity) {
  const int32_t set_point = static_cast<int32_t>(capacity / 2);
  /* Positive error => ring emptier than target => host too slow => ask for
   * MORE samples => raise feedback. Negative => the opposite. */
  const int32_t error = set_point - static_cast<int32_t>(used);

  integrator_ += error;
  if (integrator_ > integ_limit_) {
    integrator_ = integ_limit_;
  } else if (integrator_ < -integ_limit_) {
    integrator_ = -integ_limit_;
  }

  /* P term widened to int64 and computed with a multiply (not a signed left
   * shift, which is only well-defined for negative operands from C++20 on) so
   * it stays correct and overflow-free even if the ring range grows. */
  int32_t correction = static_cast<int32_t>((static_cast<int64_t>(error) * (1 << kFracBits)) / kInvKp) + integrator_ / kTi;
  if (correction > clamp_) {
    correction = clamp_;
  } else if (correction < -clamp_) {
    correction = -clamp_;
  }

  /* nominal_ dominates and correction is small & clamped, so the sum is always
   * positive; mask off the unused low bits like the Zephyr sample does. */
  int32_t val = static_cast<int32_t>(nominal_) + correction;
  val &= ~((1 << kLsbZeroBits) - 1);
  fb_value_ = static_cast<uint32_t>(val);
}

} // namespace usb_audio
```

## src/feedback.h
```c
/**
 * @file feedback.h
 * @brief Explicit-feedback regulator for the UAC2 OUT (playback) sink.
 *
 * Full-Speed only: the feedback value is Q10.14 (samples-per-SOF << 14). The
 * regulator keeps a software-timed, ring-buffered sink near half full by
 * nudging the reported samples/frame around nominal with a fixed-point PI
 * controller. Pure logic: no USB, no Zephyr, no heap, no float, no exceptions.
 *
 * @copyright Copyright (c) 2025 OE5XRX
 * @spdx-license-identifier LGPL-3.0-or-later
 */
#ifndef OE5XRX_USB_AUDIO_FEEDBACK_H_
#define OE5XRX_USB_AUDIO_FEEDBACK_H_

#include <cstddef>
#include <cstdint>

namespace usb_audio {

class BufferFeedback {
public:
  /** Set nominal value + gains for @p samples_per_sof and reset the loop. */
  void init(uint16_t samples_per_sof);

  /** Reset the integrator and set the reported value back to nominal. */
  void reset();

  /**
   * Run one control step. Call once per SOF while the OUT stream is active.
   * @param used     current ring fill, in samples
   * @param capacity ring capacity, in samples (set point is capacity/2)
   */
  void update(size_t used, size_t capacity);

  /** Current Q10.14 feedback value to report to the host. */
  uint32_t value() const { return fb_value_; }

  /** Nominal Q10.14 value (no correction). */
  uint32_t nominal() const { return nominal_; }

private:
  /* Full-Speed feedback is Q10.14. */
  static constexpr int kFracBits = 14;
  /* Clear the low bits: do not use the optional extra resolution. */
  static constexpr int kLsbZeroBits = 4;
  /* Proportional divisor: a full half-ring error (capacity/2 samples) maps to
   * ~0.5 sample of correction, i.e. the clamp. Chosen so normal few-sample
   * jitter produces only a gentle nudge. */
  static constexpr int32_t kInvKp = 256;
  /* Integral time in SOFs. The integrator carries the steady drift. */
  static constexpr int32_t kTi = 2048;

  uint32_t nominal_ = 0;    /* samples_per_sof << 14 */
  uint32_t fb_value_ = 0;   /* current reported value (clamped, LSB-masked) */
  int32_t clamp_ = 0;       /* max deviation from nominal, Q10.14 (±0.5 sample) */
  int32_t integrator_ = 0;  /* bounded accumulator (anti-windup) */
  int32_t integ_limit_ = 0; /* |integrator_| bound so I alone tops out at clamp */
};

} // namespace usb_audio

#endif /* OE5XRX_USB_AUDIO_FEEDBACK_H_ */
```
